AUTOSAR XML (schema 00052)
package /apd/AdaptiveApplicationSwComponentTypes
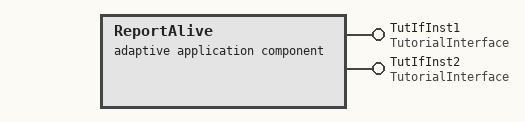
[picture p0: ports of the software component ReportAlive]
  adaptive application sw component type ReportAlive
    provide port TutIfInst1: provided-interface=TutorialInterface
    provide port TutIfInst2: provided-interface=TutorialInterface
package /apd/Executables
  executable DemonstratorTutorial: category=APPLICATION_LEVEL, minimum-timer-granularity=1000.0
    root sw component prototype ReportAlive: application-type=ReportAlive
